AUTOSAR XML (schema 4-2-2)
package /STELLANTIS/EPT/ASWCs
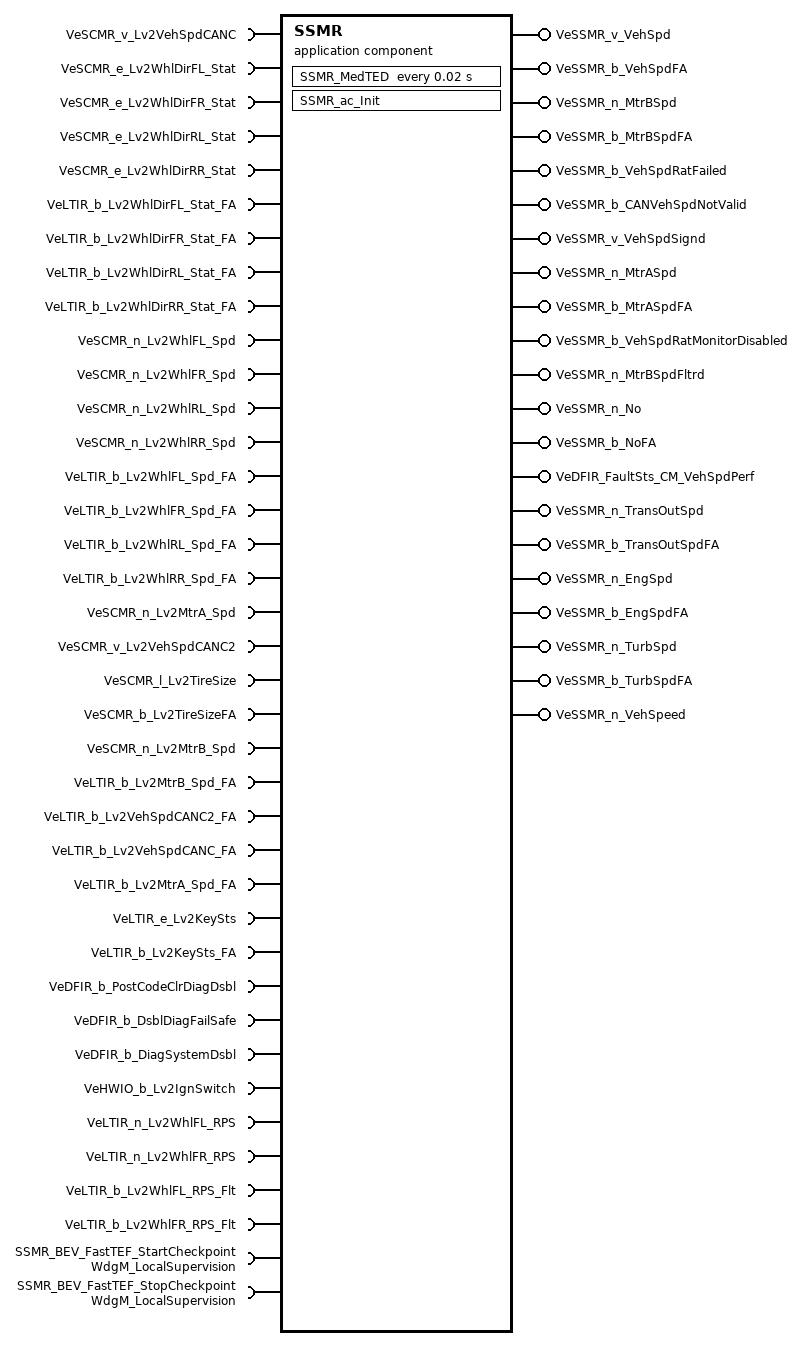
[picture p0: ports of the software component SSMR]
  application sw component type SSMR
    36 x require port:
      VeSCMR_v_Lv2VehSpdCANC: variation-point={short-label=vpVeSCMR_v_Lv2VehSpdCANC, sw-syscond=1}, nonqueued-receiver-com-spec{data-element=Value, init-value=0}, required-interface=VeSCMR_v_Lv2VehSpdCANC
      VeSCMR_e_Lv2WhlDirFL_Stat: variation-point={short-label=vpVeSCMR_e_Lv2WhlDirFL_Stat, sw-syscond=1}, nonqueued-receiver-com-spec{data-element=Value, init-value=0}, required-interface=VeSCMR_e_Lv2WhlDirFL_Stat
      VeSCMR_e_Lv2WhlDirFR_Stat: variation-point={short-label=vpVeSCMR_e_Lv2WhlDirFR_Stat, sw-syscond=1}, nonqueued-receiver-com-spec{data-element=Value, init-value=0}, required-interface=VeSCMR_e_Lv2WhlDirFR_Stat
      VeSCMR_e_Lv2WhlDirRL_Stat: variation-point={short-label=vpVeSCMR_e_Lv2WhlDirRL_Stat, sw-syscond=1}, nonqueued-receiver-com-spec{data-element=Value, init-value=0}, required-interface=VeSCMR_e_Lv2WhlDirRL_Stat
      VeSCMR_e_Lv2WhlDirRR_Stat: variation-point={short-label=vpVeSCMR_e_Lv2WhlDirRR_Stat, sw-syscond=1}, nonqueued-receiver-com-spec{data-element=Value, init-value=0}, required-interface=VeSCMR_e_Lv2WhlDirRR_Stat
      VeLTIR_b_Lv2WhlDirFL_Stat_FA: variation-point={short-label=vpVeLTIR_b_Lv2WhlDirFL_Stat_FA, sw-syscond=1}, nonqueued-receiver-com-spec{data-element=Value, init-value=0}, required-interface=VeLTIR_b_Lv2WhlDirFL_Stat_FA
      VeLTIR_b_Lv2WhlDirFR_Stat_FA: variation-point={short-label=vpVeLTIR_b_Lv2WhlDirFR_Stat_FA, sw-syscond=1}, nonqueued-receiver-com-spec{data-element=Value, init-value=0}, required-interface=VeLTIR_b_Lv2WhlDirFR_Stat_FA
      VeLTIR_b_Lv2WhlDirRL_Stat_FA: variation-point={short-label=vpVeLTIR_b_Lv2WhlDirRL_Stat_FA, sw-syscond=1}, nonqueued-receiver-com-spec{data-element=Value, init-value=0}, required-interface=VeLTIR_b_Lv2WhlDirRL_Stat_FA
      VeLTIR_b_Lv2WhlDirRR_Stat_FA: variation-point={short-label=vpVeLTIR_b_Lv2WhlDirRR_Stat_FA, sw-syscond=1}, nonqueued-receiver-com-spec{data-element=Value, init-value=0}, required-interface=VeLTIR_b_Lv2WhlDirRR_Stat_FA
      VeSCMR_n_Lv2WhlFL_Spd: variation-point={short-label=vpVeSCMR_n_Lv2WhlFL_Spd, sw-syscond=1}, nonqueued-receiver-com-spec{data-element=Value, init-value=0}, required-interface=VeSCMR_n_Lv2WhlFL_Spd
      VeSCMR_n_Lv2WhlFR_Spd: variation-point={short-label=vpVeSCMR_n_Lv2WhlFR_Spd, sw-syscond=1}, nonqueued-receiver-com-spec{data-element=Value, init-value=0}, required-interface=VeSCMR_n_Lv2WhlFR_Spd
      VeSCMR_n_Lv2WhlRL_Spd: variation-point={short-label=vpVeSCMR_n_Lv2WhlRL_Spd, sw-syscond=1}, nonqueued-receiver-com-spec{data-element=Value, init-value=0}, required-interface=VeSCMR_n_Lv2WhlRL_Spd
      VeSCMR_n_Lv2WhlRR_Spd: variation-point={short-label=vpVeSCMR_n_Lv2WhlRR_Spd, sw-syscond=1}, nonqueued-receiver-com-spec{data-element=Value, init-value=0}, required-interface=VeSCMR_n_Lv2WhlRR_Spd
      VeLTIR_b_Lv2WhlFL_Spd_FA: variation-point={short-label=vpVeLTIR_b_Lv2WhlFL_Spd_FA, sw-syscond=1}, nonqueued-receiver-com-spec{data-element=Value, init-value=0}, required-interface=VeLTIR_b_Lv2WhlFL_Spd_FA
      VeLTIR_b_Lv2WhlFR_Spd_FA: variation-point={short-label=vpVeLTIR_b_Lv2WhlFR_Spd_FA, sw-syscond=1}, nonqueued-receiver-com-spec{data-element=Value, init-value=0}, required-interface=VeLTIR_b_Lv2WhlFR_Spd_FA
      VeLTIR_b_Lv2WhlRL_Spd_FA: variation-point={short-label=vpVeLTIR_b_Lv2WhlRL_Spd_FA, sw-syscond=1}, nonqueued-receiver-com-spec{data-element=Value, init-value=0}, required-interface=VeLTIR_b_Lv2WhlRL_Spd_FA
      VeLTIR_b_Lv2WhlRR_Spd_FA: variation-point={short-label=vpVeLTIR_b_Lv2WhlRR_Spd_FA, sw-syscond=1}, nonqueued-receiver-com-spec{data-element=Value, init-value=0}, required-interface=VeLTIR_b_Lv2WhlRR_Spd_FA
      VeSCMR_n_Lv2MtrA_Spd: variation-point={short-label=vpVeSCMR_n_Lv2MtrA_Spd, sw-syscond=1}, nonqueued-receiver-com-spec{data-element=Value, init-value=0}, required-interface=VeSCMR_n_Lv2MtrA_Spd
      VeSCMR_v_Lv2VehSpdCANC2: variation-point={short-label=vpVeSCMR_v_Lv2VehSpdCANC2, sw-syscond=1}, nonqueued-receiver-com-spec{data-element=Value, init-value=0}, required-interface=VeSCMR_v_Lv2VehSpdCANC2
      VeSCMR_l_Lv2TireSize: variation-point={short-label=vpVeSCMR_l_Lv2TireSize, sw-syscond=1}, nonqueued-receiver-com-spec{data-element=Value, init-value=0}, required-interface=VeSCMR_l_Lv2TireSize
      VeSCMR_b_Lv2TireSizeFA: variation-point={short-label=vpVeSCMR_b_Lv2TireSizeFA, sw-syscond=1}, nonqueued-receiver-com-spec{data-element=Value, init-value=0}, required-interface=VeSCMR_b_Lv2TireSizeFA
      VeSCMR_n_Lv2MtrB_Spd: variation-point={short-label=vpVeSCMR_n_Lv2MtrB_Spd, sw-syscond=1}, nonqueued-receiver-com-spec{data-element=Value, init-value=0}, required-interface=VeSCMR_n_Lv2MtrB_Spd
      VeLTIR_b_Lv2MtrB_Spd_FA: variation-point={short-label=vpVeLTIR_b_Lv2MtrB_Spd_FA, sw-syscond=1}, nonqueued-receiver-com-spec{data-element=Value, init-value=0}, required-interface=VeLTIR_b_Lv2MtrB_Spd_FA
      VeLTIR_b_Lv2VehSpdCANC2_FA: variation-point={short-label=vpVeLTIR_b_Lv2VehSpdCANC2_FA, sw-syscond=1}, nonqueued-receiver-com-spec{data-element=Value, init-value=0}, required-interface=VeLTIR_b_Lv2VehSpdCANC2_FA
      VeLTIR_b_Lv2VehSpdCANC_FA: variation-point={short-label=vpVeLTIR_b_Lv2VehSpdCANC_FA, sw-syscond=1}, nonqueued-receiver-com-spec{data-element=Value, init-value=0}, required-interface=VeLTIR_b_Lv2VehSpdCANC_FA
      VeLTIR_b_Lv2MtrA_Spd_FA: variation-point={short-label=vpVeLTIR_b_Lv2MtrA_Spd_FA, sw-syscond=1}, nonqueued-receiver-com-spec{data-element=Value, init-value=0}, required-interface=VeLTIR_b_Lv2MtrA_Spd_FA
      VeLTIR_e_Lv2KeySts: variation-point={short-label=vpVeLTIR_e_Lv2KeySts, sw-syscond=1}, nonqueued-receiver-com-spec{data-element=Value, init-value=CeLTIR_e_IGN_LK}, required-interface=VeLTIR_e_Lv2KeySts
      VeLTIR_b_Lv2KeySts_FA: variation-point={short-label=vpVeLTIR_b_Lv2KeySts_FA, sw-syscond=1}, nonqueued-receiver-com-spec{data-element=Value, init-value=0}, required-interface=VeLTIR_b_Lv2KeySts_FA
      VeDFIR_b_PostCodeClrDiagDsbl: variation-point={short-label=vpVeDFIR_b_PostCodeClrDiagDsbl, sw-syscond=1}, nonqueued-receiver-com-spec{data-element=Value, init-value=0}, required-interface=VeDFIR_b_PostCodeClrDiagDsbl
      VeDFIR_b_DsblDiagFailSafe: variation-point={short-label=vpVeDFIR_b_DsblDiagFailSafe, sw-syscond=1}, nonqueued-receiver-com-spec{data-element=Value, init-value=0}, required-interface=VeDFIR_b_DsblDiagFailSafe
      VeDFIR_b_DiagSystemDsbl: variation-point={short-label=vpVeDFIR_b_DiagSystemDsbl, sw-syscond=1}, nonqueued-receiver-com-spec{data-element=Value, init-value=0}, required-interface=VeDFIR_b_DiagSystemDsbl
      VeHWIO_b_Lv2IgnSwitch: variation-point={short-label=vpVeHWIO_b_Lv2IgnSwitch, sw-syscond=1}, nonqueued-receiver-com-spec{data-element=Value, init-value=0}, required-interface=VeHWIO_b_Lv2IgnSwitch
      VeLTIR_n_Lv2WhlFL_RPS: variation-point={short-label=vpVeLTIR_n_Lv2WhlFL_RPS, sw-syscond=1}, nonqueued-receiver-com-spec{data-element=Value, init-value=0}, required-interface=VeLTIR_n_Lv2WhlFL_RPS
      VeLTIR_n_Lv2WhlFR_RPS: variation-point={short-label=vpVeLTIR_n_Lv2WhlFR_RPS, sw-syscond=1}, nonqueued-receiver-com-spec{data-element=Value, init-value=0}, required-interface=VeLTIR_n_Lv2WhlFR_RPS
      VeLTIR_b_Lv2WhlFL_RPS_Flt: variation-point={short-label=vpVeLTIR_b_Lv2WhlFL_RPS_Flt, sw-syscond=1}, nonqueued-receiver-com-spec{data-element=Value, init-value=0}, required-interface=VeLTIR_b_Lv2WhlFL_RPS_Flt
      VeLTIR_b_Lv2WhlFR_RPS_Flt: variation-point={short-label=vpVeLTIR_b_Lv2WhlFR_RPS_Flt, sw-syscond=1}, nonqueued-receiver-com-spec{data-element=Value, init-value=0}, required-interface=VeLTIR_b_Lv2WhlFR_RPS_Flt
    21 x provide port:
      VeSSMR_v_VehSpd: nonqueued-sender-com-spec{data-element=Value, init-value=0}, provided-interface=VeSSMR_v_VehSpd
      VeSSMR_b_VehSpdFA: nonqueued-sender-com-spec{data-element=Value, init-value=0}, provided-interface=VeSSMR_b_VehSpdFA
      VeSSMR_n_MtrBSpd: nonqueued-sender-com-spec{data-element=Value, init-value=0}, provided-interface=VeSSMR_n_MtrBSpd
      VeSSMR_b_MtrBSpdFA: nonqueued-sender-com-spec{data-element=Value, init-value=0}, provided-interface=VeSSMR_b_MtrBSpdFA
      VeSSMR_b_VehSpdRatFailed: nonqueued-sender-com-spec{data-element=Value, init-value=0}, provided-interface=VeSSMR_b_VehSpdRatFailed
      VeSSMR_b_CANVehSpdNotValid: nonqueued-sender-com-spec{data-element=Value, init-value=0}, provided-interface=VeSSMR_b_CANVehSpdNotValid
      VeSSMR_v_VehSpdSignd: nonqueued-sender-com-spec{data-element=Value, init-value=0}, provided-interface=VeSSMR_v_VehSpdSignd
      VeSSMR_n_MtrASpd: nonqueued-sender-com-spec{data-element=Value, init-value=0}, provided-interface=VeSSMR_n_MtrASpd
      VeSSMR_b_MtrASpdFA: nonqueued-sender-com-spec{data-element=Value, init-value=0}, provided-interface=VeSSMR_b_MtrASpdFA
      VeSSMR_b_VehSpdRatMonitorDisabled: nonqueued-sender-com-spec{data-element=Value, init-value=0}, provided-interface=VeSSMR_b_VehSpdRatMonitorDisabled
      VeSSMR_n_MtrBSpdFltrd: nonqueued-sender-com-spec{data-element=Value, init-value=0}, provided-interface=VeSSMR_n_MtrBSpdFltrd
      VeSSMR_n_No: nonqueued-sender-com-spec{data-element=Value, init-value=0}, provided-interface=VeSSMR_n_No
      VeSSMR_b_NoFA: nonqueued-sender-com-spec{data-element=Value, init-value=0}, provided-interface=VeSSMR_b_NoFA
      VeDFIR_FaultSts_CM_VehSpdPerf: nonqueued-sender-com-spec{data-element=Value, init-value=CeDFIB_e_Init}, provided-interface=VeDFIR_FaultSts_CM_VehSpdPerf
      VeSSMR_n_TransOutSpd: nonqueued-sender-com-spec{data-element=Value, init-value=0}, provided-interface=VeSSMR_n_TransOutSpd
      VeSSMR_b_TransOutSpdFA: nonqueued-sender-com-spec{data-element=Value, init-value=0}, provided-interface=VeSSMR_b_TransOutSpdFA
      VeSSMR_n_EngSpd: nonqueued-sender-com-spec{data-element=Value, init-value=0}, provided-interface=VeSSMR_n_EngSpd
      VeSSMR_b_EngSpdFA: nonqueued-sender-com-spec{data-element=Value, init-value=0}, provided-interface=VeSSMR_b_EngSpdFA
      VeSSMR_n_TurbSpd: nonqueued-sender-com-spec{data-element=Value, init-value=0}, provided-interface=VeSSMR_n_TurbSpd
      VeSSMR_b_TurbSpdFA: nonqueued-sender-com-spec{data-element=Value, init-value=0}, provided-interface=VeSSMR_b_TurbSpdFA
      VeSSMR_n_VehSpeed: nonqueued-sender-com-spec{data-element=Value, init-value=0}, provided-interface=VeSSMR_n_VehSpeed
    require port SSMR_BEV_FastTEF_StartCheckpoint: variation-point={short-label=vpSSMR_BEV_FastTEF_StartCheckpoint, sw-syscond=1}, client-com-spec=CheckpointReached, required-interface=WdgM_LocalSupervision
    require port SSMR_BEV_FastTEF_StopCheckpoint: variation-point={short-label=vpSSMR_BEV_FastTEF_StopCheckpoint, sw-syscond=1}, client-com-spec=CheckpointReached, required-interface=WdgM_LocalSupervision
    behavior IB_SSMR: data-type-mapping=msADTtoIDTMapping, handle-termination-and-restart=NO-SUPPORT
      timing event Event_MedTED: start-on-event=SSMR_MedTED, period=0.02
      init event Event_SSMR_ac_Init: start-on-event=SSMR_ac_Init
      runnable SSMR_ac_Init
        data-send-points:
          access OUT_VeDFIR_FaultSts_CM_VehSpdPerf_Value: accessed-variable=VeDFIR_FaultSts_CM_VehSpdPerf.Value
      runnable SSMR_MedTED: variation-point={short-label=vpSSMR_MedTED, sw-syscond=1}
        data-receive-point-by-arguments:
          36 x access:
            IN_VeDFIR_b_DiagSystemDsbl_Value: accessed-variable=VeDFIR_b_DiagSystemDsbl.Value, variation-point={short-label=vpIN_VeDFIR_b_DiagSystemDsbl_Value, sw-syscond=1}
            IN_VeDFIR_b_DsblDiagFailSafe_Value: accessed-variable=VeDFIR_b_DsblDiagFailSafe.Value, variation-point={short-label=vpIN_VeDFIR_b_DsblDiagFailSafe_Value, sw-syscond=1}
            IN_VeDFIR_b_PostCodeClrDiagDsbl_Value: accessed-variable=VeDFIR_b_PostCodeClrDiagDsbl.Value, variation-point={short-label=vpIN_VeDFIR_b_PostCodeClrDiagDsbl_Value, sw-syscond=1}
            IN_VeHWIO_b_Lv2IgnSwitch_Value: accessed-variable=VeHWIO_b_Lv2IgnSwitch.Value, variation-point={short-label=vpIN_VeHWIO_b_Lv2IgnSwitch_Value, sw-syscond=1}
            IN_VeLTIR_b_Lv2KeySts_FA_Value: accessed-variable=VeLTIR_b_Lv2KeySts_FA.Value, variation-point={short-label=vpIN_VeLTIR_b_Lv2KeySts_FA_Value, sw-syscond=1}
            IN_VeLTIR_b_Lv2MtrA_Spd_FA_Value: accessed-variable=VeLTIR_b_Lv2MtrA_Spd_FA.Value, variation-point={short-label=vpIN_VeLTIR_b_Lv2MtrA_Spd_FA_Value, sw-syscond=1}
            IN_VeLTIR_b_Lv2MtrB_Spd_FA_Value: accessed-variable=VeLTIR_b_Lv2MtrB_Spd_FA.Value, variation-point={short-label=vpIN_VeLTIR_b_Lv2MtrB_Spd_FA_Value, sw-syscond=1}
            IN_VeLTIR_b_Lv2VehSpdCANC2_FA_Value: accessed-variable=VeLTIR_b_Lv2VehSpdCANC2_FA.Value, variation-point={short-label=vpIN_VeLTIR_b_Lv2VehSpdCANC2_FA_Value, sw-syscond=1}
            IN_VeLTIR_b_Lv2VehSpdCANC_FA_Value: accessed-variable=VeLTIR_b_Lv2VehSpdCANC_FA.Value, variation-point={short-label=vpIN_VeLTIR_b_Lv2VehSpdCANC_FA_Value, sw-syscond=1}
            IN_VeLTIR_b_Lv2WhlDirFL_Stat_FA_Value: accessed-variable=VeLTIR_b_Lv2WhlDirFL_Stat_FA.Value, variation-point={short-label=vpIN_VeLTIR_b_Lv2WhlDirFL_Stat_FA_Value, sw-syscond=1}
            IN_VeLTIR_b_Lv2WhlDirFR_Stat_FA_Value: accessed-variable=VeLTIR_b_Lv2WhlDirFR_Stat_FA.Value, variation-point={short-label=vpIN_VeLTIR_b_Lv2WhlDirFR_Stat_FA_Value, sw-syscond=1}
            IN_VeLTIR_b_Lv2WhlDirRL_Stat_FA_Value: accessed-variable=VeLTIR_b_Lv2WhlDirRL_Stat_FA.Value, variation-point={short-label=vpIN_VeLTIR_b_Lv2WhlDirRL_Stat_FA_Value, sw-syscond=1}
            IN_VeLTIR_b_Lv2WhlDirRR_Stat_FA_Value: accessed-variable=VeLTIR_b_Lv2WhlDirRR_Stat_FA.Value, variation-point={short-label=vpIN_VeLTIR_b_Lv2WhlDirRR_Stat_FA_Value, sw-syscond=1}
            IN_VeLTIR_b_Lv2WhlFL_RPS_Flt_Value: accessed-variable=VeLTIR_b_Lv2WhlFL_RPS_Flt.Value, variation-point={short-label=vpIN_VeLTIR_b_Lv2WhlFL_RPS_Flt_Value, sw-syscond=1}
            IN_VeLTIR_b_Lv2WhlFL_Spd_FA_Value: accessed-variable=VeLTIR_b_Lv2WhlFL_Spd_FA.Value, variation-point={short-label=vpIN_VeLTIR_b_Lv2WhlFL_Spd_FA_Value, sw-syscond=1}
            IN_VeLTIR_b_Lv2WhlFR_RPS_Flt_Value: accessed-variable=VeLTIR_b_Lv2WhlFR_RPS_Flt.Value, variation-point={short-label=vpIN_VeLTIR_b_Lv2WhlFR_RPS_Flt_Value, sw-syscond=1}
            IN_VeLTIR_b_Lv2WhlFR_Spd_FA_Value: accessed-variable=VeLTIR_b_Lv2WhlFR_Spd_FA.Value, variation-point={short-label=vpIN_VeLTIR_b_Lv2WhlFR_Spd_FA_Value, sw-syscond=1}
            IN_VeLTIR_b_Lv2WhlRL_Spd_FA_Value: accessed-variable=VeLTIR_b_Lv2WhlRL_Spd_FA.Value, variation-point={short-label=vpIN_VeLTIR_b_Lv2WhlRL_Spd_FA_Value, sw-syscond=1}
            IN_VeLTIR_b_Lv2WhlRR_Spd_FA_Value: accessed-variable=VeLTIR_b_Lv2WhlRR_Spd_FA.Value, variation-point={short-label=vpIN_VeLTIR_b_Lv2WhlRR_Spd_FA_Value, sw-syscond=1}
            IN_VeLTIR_e_Lv2KeySts_Value: accessed-variable=VeLTIR_e_Lv2KeySts.Value, variation-point={short-label=vpIN_VeLTIR_e_Lv2KeySts_Value, sw-syscond=1}
            IN_VeLTIR_n_Lv2WhlFL_RPS_Value: accessed-variable=VeLTIR_n_Lv2WhlFL_RPS.Value, variation-point={short-label=vpIN_VeLTIR_n_Lv2WhlFL_RPS_Value, sw-syscond=1}
            IN_VeLTIR_n_Lv2WhlFR_RPS_Value: accessed-variable=VeLTIR_n_Lv2WhlFR_RPS.Value, variation-point={short-label=vpIN_VeLTIR_n_Lv2WhlFR_RPS_Value, sw-syscond=1}
            IN_VeSCMR_b_Lv2TireSizeFA_Value: accessed-variable=VeSCMR_b_Lv2TireSizeFA.Value, variation-point={short-label=vpIN_VeSCMR_b_Lv2TireSizeFA_Value, sw-syscond=1}
            IN_VeSCMR_e_Lv2WhlDirFL_Stat_Value: accessed-variable=VeSCMR_e_Lv2WhlDirFL_Stat.Value, variation-point={short-label=vpIN_VeSCMR_e_Lv2WhlDirFL_Stat_Value, sw-syscond=1}
            IN_VeSCMR_e_Lv2WhlDirFR_Stat_Value: accessed-variable=VeSCMR_e_Lv2WhlDirFR_Stat.Value, variation-point={short-label=vpIN_VeSCMR_e_Lv2WhlDirFR_Stat_Value, sw-syscond=1}
            IN_VeSCMR_e_Lv2WhlDirRL_Stat_Value: accessed-variable=VeSCMR_e_Lv2WhlDirRL_Stat.Value, variation-point={short-label=vpIN_VeSCMR_e_Lv2WhlDirRL_Stat_Value, sw-syscond=1}
            IN_VeSCMR_e_Lv2WhlDirRR_Stat_Value: accessed-variable=VeSCMR_e_Lv2WhlDirRR_Stat.Value, variation-point={short-label=vpIN_VeSCMR_e_Lv2WhlDirRR_Stat_Value, sw-syscond=1}
            IN_VeSCMR_l_Lv2TireSize_Value: accessed-variable=VeSCMR_l_Lv2TireSize.Value, variation-point={short-label=vpIN_VeSCMR_l_Lv2TireSize_Value, sw-syscond=1}
            IN_VeSCMR_n_Lv2MtrA_Spd_Value: accessed-variable=VeSCMR_n_Lv2MtrA_Spd.Value, variation-point={short-label=vpIN_VeSCMR_n_Lv2MtrA_Spd_Value, sw-syscond=1}
            IN_VeSCMR_n_Lv2MtrB_Spd_Value: accessed-variable=VeSCMR_n_Lv2MtrB_Spd.Value, variation-point={short-label=vpIN_VeSCMR_n_Lv2MtrB_Spd_Value, sw-syscond=1}
            IN_VeSCMR_n_Lv2WhlFL_Spd_Value: accessed-variable=VeSCMR_n_Lv2WhlFL_Spd.Value, variation-point={short-label=vpIN_VeSCMR_n_Lv2WhlFL_Spd_Value, sw-syscond=1}
            IN_VeSCMR_n_Lv2WhlFR_Spd_Value: accessed-variable=VeSCMR_n_Lv2WhlFR_Spd.Value, variation-point={short-label=vpIN_VeSCMR_n_Lv2WhlFR_Spd_Value, sw-syscond=1}
            IN_VeSCMR_n_Lv2WhlRL_Spd_Value: accessed-variable=VeSCMR_n_Lv2WhlRL_Spd.Value, variation-point={short-label=vpIN_VeSCMR_n_Lv2WhlRL_Spd_Value, sw-syscond=1}
            IN_VeSCMR_n_Lv2WhlRR_Spd_Value: accessed-variable=VeSCMR_n_Lv2WhlRR_Spd.Value, variation-point={short-label=vpIN_VeSCMR_n_Lv2WhlRR_Spd_Value, sw-syscond=1}
            IN_VeSCMR_v_Lv2VehSpdCANC_Value: accessed-variable=VeSCMR_v_Lv2VehSpdCANC.Value, variation-point={short-label=vpIN_VeSCMR_v_Lv2VehSpdCANC_Value, sw-syscond=1}
            IN_VeSCMR_v_Lv2VehSpdCANC2_Value: accessed-variable=VeSCMR_v_Lv2VehSpdCANC2.Value, variation-point={short-label=vpIN_VeSCMR_v_Lv2VehSpdCANC2_Value, sw-syscond=1}
        data-send-points:
          9 x access:
            OUT_VeSSMR_v_VehSpd_Value: accessed-variable=VeSSMR_v_VehSpd.Value
            OUT_VeSSMR_b_VehSpdFA_Value: accessed-variable=VeSSMR_b_VehSpdFA.Value
            OUT_VeSSMR_n_MtrBSpd_Value: accessed-variable=VeSSMR_n_MtrBSpd.Value
            OUT_VeSSMR_b_MtrBSpdFA_Value: accessed-variable=VeSSMR_b_MtrBSpdFA.Value
            OUT_VeSSMR_b_VehSpdRatFailed_Value: accessed-variable=VeSSMR_b_VehSpdRatFailed.Value
            OUT_VeSSMR_b_CANVehSpdNotValid_Value: accessed-variable=VeSSMR_b_CANVehSpdNotValid.Value
            OUT_VeSSMR_v_VehSpdSignd_Value: accessed-variable=VeSSMR_v_VehSpdSignd.Value
            OUT_VeSSMR_n_MtrASpd_Value: accessed-variable=VeSSMR_n_MtrASpd.Value
            OUT_VeSSMR_b_MtrASpdFA_Value: accessed-variable=VeSSMR_b_MtrASpdFA.Value
        sync call SC_SSMR_BEV_FastTEF_StartCheckpoint_CheckpointReached: operation=SSMR_BEV_FastTEF_StartCheckpoint.CheckpointReached, timeout=1E-06, variation-point={short-label=vpSC_SSMR_BEV_FastTEF_StartCheckpoint_CheckpointReached, sw-syscond=1}
        sync call SC_SSMR_BEV_FastTEF_StopCheckpoint_CheckpointReached: operation=SSMR_BEV_FastTEF_StopCheckpoint.CheckpointReached, timeout=1E-06, variation-point={short-label=vpSC_SSMR_BEV_FastTEF_StopCheckpoint_CheckpointReached, sw-syscond=1}
      variation point proxy Variant_SSMR_Bev: category=CONDITION, condition-access=1
      variation point proxy Variant_SSMR_Func: category=CONDITION, condition-access=0
      variation point proxy Variant_SSMR_P1fPx: category=CONDITION, condition-access=0
